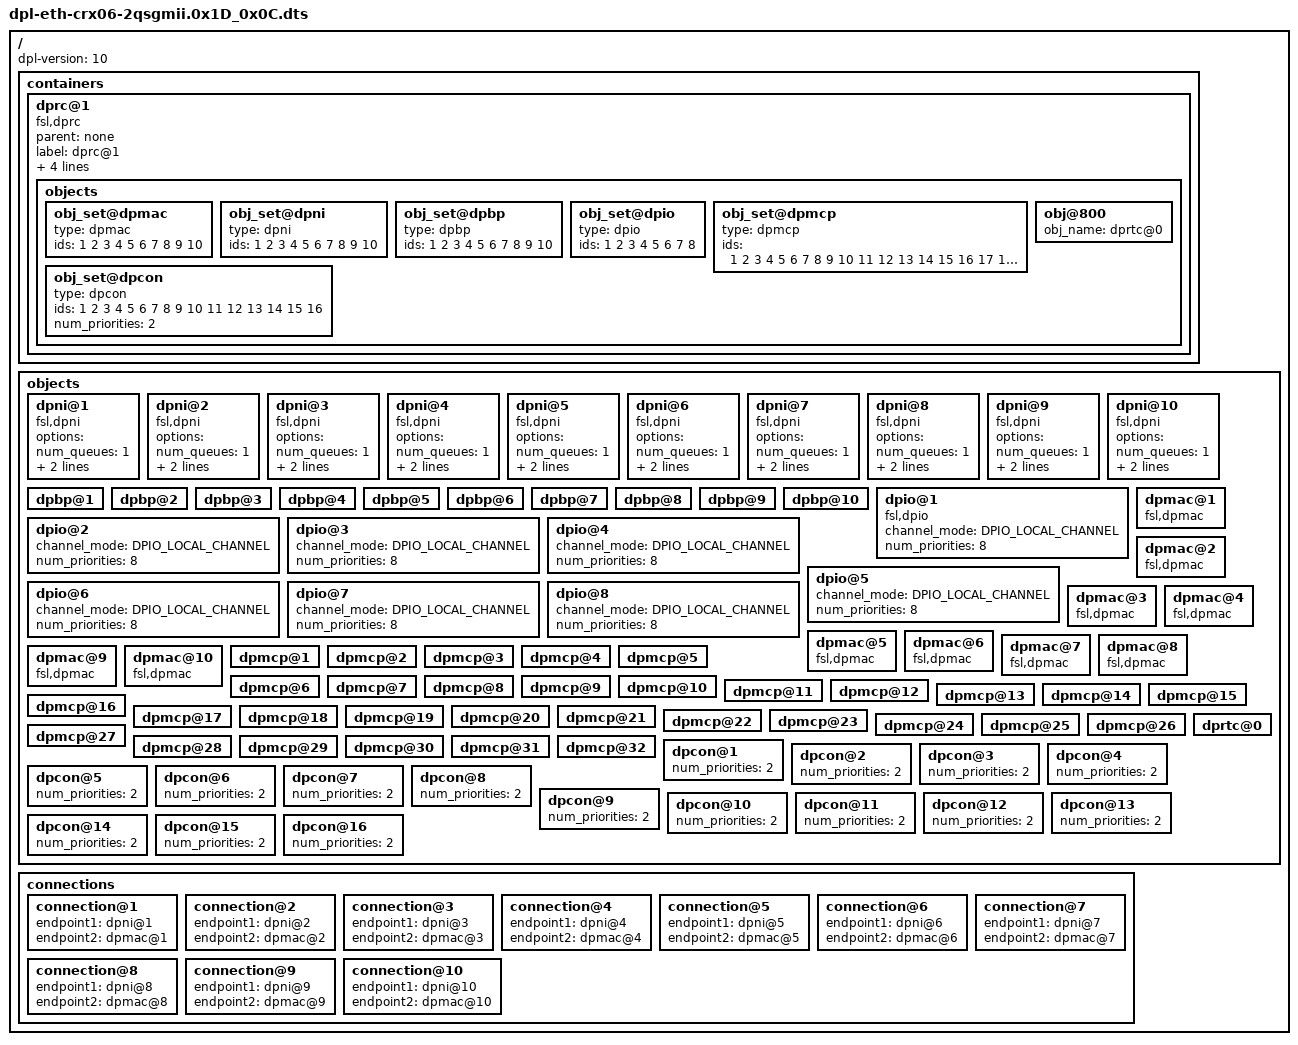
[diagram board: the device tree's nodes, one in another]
/*
 * Copyright 2016 Freescale Semiconductor, Inc.
 * Copyright 2017 NXP
 * Copyright 2019 MicroSys Electronics GmbH
 *
 * Redistribution and use in source and binary forms, with or without
 * modification, are permitted provided that the following conditions are met:
 *   * Redistributions of source code must retain the above copyright
 *     notice, this list of conditions and the following disclaimer.
 *   * Redistributions in binary form must reproduce the above copyright
 *     notice, this list of conditions and the following disclaimer in the
 *     documentation and/or other materials provided with the distribution.
 *   * Neither the name of the above-listed copyright holders nor the
 *     names of any contributors may be used to endorse or promote products
 *     derived from this software without specific prior written permission.
 *
 * THIS SOFTWARE IS PROVIDED BY THE COPYRIGHT HOLDERS AND CONTRIBUTORS "AS IS"
 * AND ANY EXPRESS OR IMPLIED WARRANTIES, INCLUDING, BUT NOT LIMITED TO, THE
 * IMPLIED WARRANTIES OF MERCHANTABILITY AND FITNESS FOR A PARTICULAR PURPOSE
 * ARE DISCLAIMED. IN NO EVENT SHALL THE COPYRIGHT HOLDERS OR CONTRIBUTORS BE
 * LIABLE FOR ANY DIRECT, INDIRECT, INCIDENTAL, SPECIAL, EXEMPLARY, OR
 * CONSEQUENTIAL DAMAGES (INCLUDING, BUT NOT LIMITED TO, PROCUREMENT OF
 * SUBSTITUTE GOODS OR SERVICES; LOSS OF USE, DATA, OR PROFITS; OR BUSINESS
 * INTERRUPTION) HOWEVER CAUSED AND ON ANY THEORY OF LIABILITY, WHETHER IN
 * CONTRACT, STRICT LIABILITY, OR TORT (INCLUDING NEGLIGENCE OR OTHERWISE)
 * ARISING IN ANY WAY OUT OF THE USE OF THIS SOFTWARE, EVEN IF ADVISED OF THE
 * POSSIBILITY OF SUCH DAMAGE.
 */

/*
 * "Bootstrap DPL" for ls1088a featuring SerDes 0x1D_0x0D.
 * This together with the available DPMCP objects should be enough to boot Linux
 * and to allow the dynamic addition of other objects to the Linux container,
 * using the 'restool' utility.
 */
/dts-v1/;
/ {
	dpl-version = <10>;
	/*****************************************************************
	 * Containers
	 *****************************************************************/
	containers {
		dprc@1 {
			compatible = "fsl,dprc";
			parent = "none";
			label = "dprc@1";
			options = "DPRC_CFG_OPT_SPAWN_ALLOWED" , "DPRC_CFG_OPT_ALLOC_ALLOWED", "DPRC_CFG_OPT_IRQ_CFG_ALLOWED","DPRC_CFG_OPT_OBJ_CREATE_ALLOWED";
			objects {
				/* ------------- MACs --------------*/
				obj_set@dpmac {
					type = "dpmac";
					ids = <1 2 3 4 5 6 7 8 9 10>;
				};

				/* ------------ DPNIs --------------*/
				obj_set@dpni {
					type = "dpni";
					ids = <1 2 3 4 5 6 7 8 9 10>;
				};

				/* ------------ DPBPs --------------*/
				obj_set@dpbp {
					type = "dpbp";
					ids = <1 2 3 4 5 6 7 8 9 10>;
				};

				/* ------------ DPCIs --------------*/
				/*
				obj_set@dpci {
					type = "dpci";
					ids = <1 2 3 4 5 6 7 8 9 10>;
				};
				*/

				/* ------------ DPIOs --------------*/
				/* One for every core: */
				obj_set@dpio {
					type = "dpio";
					ids = <1 2 3 4 5 6 7 8>;
				};

				/* ------------ DPMCPs --------------*/
				obj_set@dpmcp {
					type = "dpmcp";
					ids = < 1  2  3  4  5  6  7  8  9 10 11 12 13 14 15 16 17 18 19 20 21 22 23 24 25 26 27 28 29 30
					       31 32>;
				};

				/* ------------ DPCON --------------*/
				obj_set@dpcon {
					type = "dpcon";
					ids = <1 2 3 4 5 6 7 8 9 10 11 12 13 14 15 16>;
					num_priorities=<2>;
				};

				/* ------------ DPRTC --------------*/
				obj@800 {
					obj_name="dprtc@0";
				};
			};
		};
	};

	/*****************************************************************
	 * Objects
	 *****************************************************************/
	objects {

		/* ------------ DPNI --------------*/

		dpni@1 {
			compatible = "fsl,dpni";
			options = "";
			num_queues = <1>;
			num_tcs = <1>;
			fs_entries = <16>;
		};

		dpni@2 {
			compatible = "fsl,dpni";
			options = "";
			num_queues = <1>;
			num_tcs = <1>;
			fs_entries = <16>;
		};

		dpni@3 {
			compatible = "fsl,dpni";
			options = "";
			num_queues = <1>;
			num_tcs = <1>;
			fs_entries = <16>;
		};

		dpni@4 {
			compatible = "fsl,dpni";
			options = "";
			num_queues = <1>;
			num_tcs = <1>;
			fs_entries = <16>;
		};

		dpni@5 {
			compatible = "fsl,dpni";
			options = "";
			num_queues = <1>;
			num_tcs = <1>;
			fs_entries = <16>;
		};

		dpni@6 {
			compatible = "fsl,dpni";
			options = "";
			num_queues = <1>;
			num_tcs = <1>;
			fs_entries = <16>;
		};

		dpni@7 {
			compatible = "fsl,dpni";
			options = "";
			num_queues = <1>;
			num_tcs = <1>;
			fs_entries = <16>;
		};

		dpni@8 {
			compatible = "fsl,dpni";
			options = "";
			num_queues = <1>;
			num_tcs = <1>;
			fs_entries = <16>;
		};

		dpni@9 {
			compatible = "fsl,dpni";
			options = "";
			num_queues = <1>;
			num_tcs = <1>;
			fs_entries = <16>;
		};

		dpni@10 {
			compatible = "fsl,dpni";
			options = "";
			num_queues = <1>;
			num_tcs = <1>;
			fs_entries = <16>;
		};

		/* ------------ DPBP --------------*/
		dpbp@1 {
		};
		dpbp@2 {
		};
		dpbp@3 {
		};
		dpbp@4 {
		};
		dpbp@5 {
		};
		dpbp@6 {
		};
		dpbp@7 {
		};
		dpbp@8 {
		};
		dpbp@9 {
		};
		dpbp@10 {
		};

		/* ------------ DPCI --------------*/
		/*
		dpci@1 {
			num_priorities = <2>;
		};
		dpci@2 {
			num_priorities = <2>;
		};
		dpci@3 {
			num_priorities = <2>;
		};
		dpci@4 {
			num_priorities = <2>;
		};
		dpci@5 {
			num_priorities = <2>;
		};
		dpci@6 {
			num_priorities = <2>;
		};
		dpci@7 {
			num_priorities = <2>;
		};
		dpci@8 {
			num_priorities = <2>;
		};
		dpci@9 {
			num_priorities = <2>;
		};
		dpci@10 {
			num_priorities = <2>;
		};
		*/

		/* ------------ DPIO --------------*/
		dpio@1 {
			compatible = "fsl,dpio";
			channel_mode = "DPIO_LOCAL_CHANNEL";
			num_priorities = <8>;
		};
		dpio@2 {
			channel_mode = "DPIO_LOCAL_CHANNEL";
			num_priorities = <8>;
		};
		dpio@3 {
			channel_mode = "DPIO_LOCAL_CHANNEL";
			num_priorities = <8>;
		};
		dpio@4 {
			channel_mode = "DPIO_LOCAL_CHANNEL";
			num_priorities = <8>;
		};
		dpio@5 {
			channel_mode = "DPIO_LOCAL_CHANNEL";
			num_priorities = <8>;
		};
		dpio@6 {
			channel_mode = "DPIO_LOCAL_CHANNEL";
			num_priorities = <8>;
		};
		dpio@7 {
			channel_mode = "DPIO_LOCAL_CHANNEL";
			num_priorities = <8>;
		};
		dpio@8 {
			channel_mode = "DPIO_LOCAL_CHANNEL";
			num_priorities = <8>;
		};

		/* ------------ DPMAC --------------*/
		dpmac@1 {
			compatible = "fsl,dpmac";
		};
		dpmac@2 {
			compatible = "fsl,dpmac";
		};
		dpmac@3 {
			compatible = "fsl,dpmac";
		};
		dpmac@4 {
			compatible = "fsl,dpmac";
		};
		dpmac@5 {
			compatible = "fsl,dpmac";
		};
		dpmac@6 {
			compatible = "fsl,dpmac";
		};
		dpmac@7 {
			compatible = "fsl,dpmac";
		};
		dpmac@8 {
			compatible = "fsl,dpmac";
		};
		dpmac@9 {
			compatible = "fsl,dpmac";
		};
		dpmac@10 {
			compatible = "fsl,dpmac";
		};

		/* ------------ DPMCP --------------*/
		dpmcp@1 {
		};
		dpmcp@2 {
		};
		dpmcp@3 {
		};
		dpmcp@4 {
		};
		dpmcp@5 {
		};
		dpmcp@6 {
		};
		dpmcp@7 {
		};
		dpmcp@8 {
		};
		dpmcp@9 {
		};
		dpmcp@10 {
		};
		dpmcp@11 {
		};
		dpmcp@12 {
		};
		dpmcp@13 {
		};
		dpmcp@14 {
		};
		dpmcp@15 {
		};
		dpmcp@16 {
		};
		dpmcp@17 {
		};
		dpmcp@18 {
		};
		dpmcp@19 {
		};
		dpmcp@20 {
		};
		dpmcp@21 {
		};
		dpmcp@22 {
		};
		dpmcp@23 {
		};
		dpmcp@24 {
		};
		dpmcp@25 {
		};
		dpmcp@26 {
		};
		dpmcp@27 {
		};
		dpmcp@28 {
		};
		dpmcp@29 {
		};
		dpmcp@30 {
		};
		dpmcp@31 {
		};
		dpmcp@32 {
		};

		/* ------------ DPCON --------------*/
		dpcon@1 {
			num_priorities=<2>;
		};
		dpcon@2 {
			num_priorities=<2>;
		};
		dpcon@3 {
			num_priorities=<2>;
		};
		dpcon@4 {
			num_priorities=<2>;
		};
		dpcon@5 {
			num_priorities=<2>;
		};
		dpcon@6 {
			num_priorities=<2>;
		};
		dpcon@7 {
			num_priorities=<2>;
		};
		dpcon@8 {
			num_priorities=<2>;
		};
		dpcon@9 {
			num_priorities=<2>;
		};
		dpcon@10 {
			num_priorities=<2>;
		};
		dpcon@11 {
			num_priorities=<2>;
		};
		dpcon@12 {
			num_priorities=<2>;
		};
		dpcon@13 {
			num_priorities=<2>;
		};
		dpcon@14 {
			num_priorities=<2>;
		};
		dpcon@15 {
			num_priorities=<2>;
		};
		dpcon@16 {
			num_priorities=<2>;
		};

		/* ------------ DPRTC --------------*/
		dprtc@0 {
		};
	};

	/*****************************************************************
	 * Connections
	 *****************************************************************/
	connections {
		connection@1{
			endpoint1 = "dpni@1";
			endpoint2 = "dpmac@1";
		};
		connection@2{
			endpoint1 = "dpni@2";
			endpoint2 = "dpmac@2";
		};
		connection@3{
			endpoint1 = "dpni@3";
			endpoint2 = "dpmac@3";
		};
		connection@4{
			endpoint1 = "dpni@4";
			endpoint2 = "dpmac@4";
		};
		connection@5{
			endpoint1 = "dpni@5";
			endpoint2 = "dpmac@5";
		};
		connection@6{
			endpoint1 = "dpni@6";
			endpoint2 = "dpmac@6";
		};
		connection@7{
			endpoint1 = "dpni@7";
			endpoint2 = "dpmac@7";
		};
		connection@8{
			endpoint1 = "dpni@8";
			endpoint2 = "dpmac@8";
		};
		connection@9{
			endpoint1 = "dpni@9";
			endpoint2 = "dpmac@9";
		};
		connection@10{
			endpoint1 = "dpni@10";
			endpoint2 = "dpmac@10";
		};
	};
};
